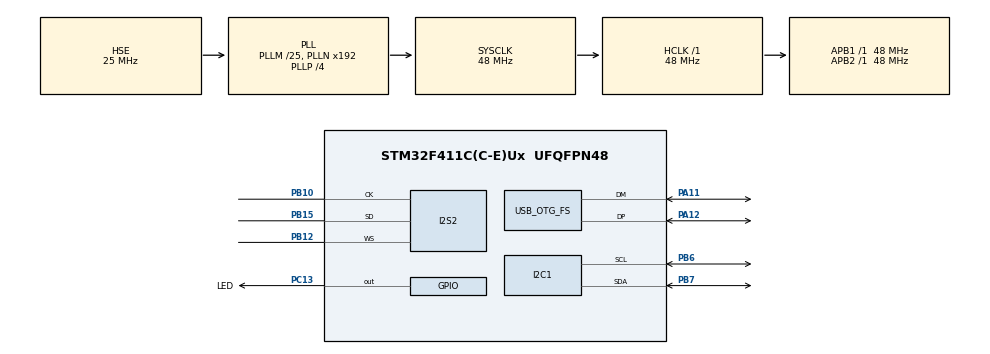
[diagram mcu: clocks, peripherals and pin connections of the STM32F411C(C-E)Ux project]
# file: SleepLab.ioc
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Dma.Request0=SPI2_RX
Dma.SPI2_RX.0.Direction=DMA_PERIPH_TO_MEMORY
Dma.SPI2_RX.0.FIFOMode=DMA_FIFOMODE_DISABLE
Dma.SPI2_RX.0.Instance=DMA1_Stream3
Dma.SPI2_RX.0.MemDataAlignment=DMA_MDATAALIGN_HALFWORD
Dma.SPI2_RX.0.MemInc=DMA_MINC_ENABLE
Dma.SPI2_RX.0.Mode=DMA_CIRCULAR
Dma.SPI2_RX.0.PeriphDataAlignment=DMA_PDATAALIGN_HALFWORD
Dma.SPI2_RX.0.PeriphInc=DMA_PINC_DISABLE
Dma.SPI2_RX.0.Priority=DMA_PRIORITY_LOW
I2S2.AudioFreq=I2S_AUDIOFREQ_32K
I2S2.DataFormat=I2S_DATAFORMAT_24B
I2S2.ErrorAudioFreq=0.33 %
I2S2.FullDuplexMode=I2S_FULLDUPLEXMODE_DISABLE
I2S2.Instance=SPI$Index
I2S2.Mode=I2S_MODE_MASTER_RX
I2S2.RealAudioFreq=32.106 KHz
I2S2.VirtualMode=I2S_MODE_MASTER
Mcu.Family=STM32F4
Mcu.Name=STM32F411C(C-E)Ux
Mcu.Package=UFQFPN48
NVIC.DMA1_Stream3_IRQn=true\:5\:0\:true\:false\:true\:false\:true\:true
NVIC.OTG_FS_IRQn=true\:0\:0\:true\:false\:true\:true\:true\:true
NVIC.PriorityGroup=NVIC_PRIORITYGROUP_4
PA11.Mode=Device_Only
PA11.Signal=USB_OTG_FS_DM
PA12.Mode=Device_Only
PA12.Signal=USB_OTG_FS_DP
PA13.Mode=Serial_Wire
PA13.Signal=SYS_JTMS-SWDIO
PA14.Mode=Serial_Wire
PA14.Signal=SYS_JTCK-SWCLK
PB10.Mode=Half_Duplex_Master
PB10.Signal=I2S2_CK
PB12.Mode=Half_Duplex_Master
PB12.Signal=I2S2_WS
PB15.Mode=Half_Duplex_Master
PB15.Signal=I2S2_SD
PB6.Mode=I2C
PB6.Signal=I2C1_SCL
PB7.Mode=I2C
PB7.Signal=I2C1_SDA
PC13-ANTI_TAMP.GPIO_Label=LED
PC13-ANTI_TAMP.GPIO_ModeDefaultOutputPP=GPIO_MODE_OUTPUT_PP
PC13-ANTI_TAMP.PinState=GPIO_PIN_SET
PC13-ANTI_TAMP.Signal=GPIO_Output
PH0\ -\ OSC_IN.Mode=HSE-External-Oscillator
PH0\ -\ OSC_IN.Signal=RCC_OSC_IN
PH1\ -\ OSC_OUT.Mode=HSE-External-Oscillator
PH1\ -\ OSC_OUT.Signal=RCC_OSC_OUT
ProjectManager.HeapSize=0x200
ProjectManager.StackSize=0x400
ProjectManager.TargetToolchain=CMake
RCC.48MHZClocksFreq_Value=48000000
RCC.AHBFreq_Value=48000000
RCC.APB1Freq_Value=48000000
RCC.APB1TimFreq_Value=48000000
RCC.APB2Freq_Value=48000000
RCC.APB2TimFreq_Value=48000000
RCC.CortexFreq_Value=48000000
RCC.HCLKFreq_Value=48000000
RCC.HSE_VALUE=25000000
RCC.HSI_VALUE=16000000
RCC.LSE_VALUE=32768
RCC.PLLM=25
RCC.PLLP=RCC_PLLP_DIV4
RCC.SYSCLKFreq_VALUE=48000000
RCC.SYSCLKSource=RCC_SYSCLKSOURCE_PLLCLK
RCC.VCOOutputFreq_Value=192000000
USB_DEVICE.CLASS_NAME_FS=CDC
USB_DEVICE.VirtualMode=Cdc
USB_DEVICE.VirtualModeFS=Cdc_FS
USB_OTG_FS.VirtualMode=Device_Only
VP_USB_DEVICE_VS_USB_DEVICE_CDC_FS.Mode=CDC_FS
board=custom

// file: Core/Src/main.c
/* USER CODE BEGIN Header */
/**
  ******************************************************************************
  * @file           : main.c
  * @brief          : Main program body
  ******************************************************************************
  * @attention
  *
  * Copyright (c) 2026 STMicroelectronics.
  * All rights reserved.
  *
  * This software is licensed under terms that can be found in the LICENSE file
  * in the root directory of this software component.
  * If no LICENSE file comes with this software, it is provided AS-IS.
  *
  ******************************************************************************
  */
/* USER CODE END Header */
#include "main.h"
#include "usb_device.h"

/* USER CODE BEGIN Includes */
#include "app.h"
#include "audio.h"
/* USER CODE END Includes */

I2C_HandleTypeDef hi2c1;

I2S_HandleTypeDef hi2s2;
DMA_HandleTypeDef hdma_spi2_rx;

void SystemClock_Config(void);
static void MX_GPIO_Init(void);
static void MX_DMA_Init(void);
static void MX_I2C1_Init(void);
static void MX_I2S2_Init(void);

int main(void)
{

  /* MCU Configuration--------------------------------------------------------*/

  /* Reset of all peripherals, Initializes the Flash interface and the Systick. */
  HAL_Init();

  /* Configure the system clock */
  SystemClock_Config();

  /* Initialize all configured peripherals */
  MX_GPIO_Init();
  MX_DMA_Init();
  MX_I2C1_Init();
  MX_USB_DEVICE_Init();
  MX_I2S2_Init();
  /* USER CODE BEGIN 2 */

  App_Init(&hi2c1);

  if (Audio_Start(&hi2s2) != HAL_OK){
      Error_Handler();
  }

  /* USER CODE END 2 */

  /* Infinite loop */
  while (1){

    /* USER CODE BEGIN 3 */
      Audio_Process();
      Audio_Update(HAL_GetTick());
      App_Update();
      __WFI();
  }
  /* USER CODE END 3 */
}

void SystemClock_Config(void)
{
  RCC_OscInitTypeDef RCC_OscInitStruct = {0};
  RCC_ClkInitTypeDef RCC_ClkInitStruct = {0};

  /** Configure the main internal regulator output voltage
  */
  __HAL_RCC_PWR_CLK_ENABLE();
  __HAL_PWR_VOLTAGESCALING_CONFIG(PWR_REGULATOR_VOLTAGE_SCALE1);

  /** Initializes the RCC Oscillators according to the specified parameters
  * in the RCC_OscInitTypeDef structure.
  */
  RCC_OscInitStruct.OscillatorType = RCC_OSCILLATORTYPE_HSE;
  RCC_OscInitStruct.HSEState = RCC_HSE_ON;
  RCC_OscInitStruct.PLL.PLLState = RCC_PLL_ON;
  RCC_OscInitStruct.PLL.PLLSource = RCC_PLLSOURCE_HSE;
  RCC_OscInitStruct.PLL.PLLM = 25;
  RCC_OscInitStruct.PLL.PLLN = 192;
  RCC_OscInitStruct.PLL.PLLP = RCC_PLLP_DIV4;
  RCC_OscInitStruct.PLL.PLLQ = 4;
  if (HAL_RCC_OscConfig(&RCC_OscInitStruct) != HAL_OK)
  {
    Error_Handler();
  }

  /** Initializes the CPU, AHB and APB buses clocks
  */
  RCC_ClkInitStruct.ClockType = RCC_CLOCKTYPE_HCLK|RCC_CLOCKTYPE_SYSCLK
                              |RCC_CLOCKTYPE_PCLK1|RCC_CLOCKTYPE_PCLK2;
  RCC_ClkInitStruct.SYSCLKSource = RCC_SYSCLKSOURCE_PLLCLK;
  RCC_ClkInitStruct.AHBCLKDivider = RCC_SYSCLK_DIV1;
  RCC_ClkInitStruct.APB1CLKDivider = RCC_HCLK_DIV1;
  RCC_ClkInitStruct.APB2CLKDivider = RCC_HCLK_DIV1;

  if (HAL_RCC_ClockConfig(&RCC_ClkInitStruct, FLASH_LATENCY_1) != HAL_OK)
  {
    Error_Handler();
  }
}

static void MX_I2C1_Init(void)
{

  hi2c1.Instance = I2C1;
  hi2c1.Init.ClockSpeed = 100000;
  hi2c1.Init.DutyCycle = I2C_DUTYCYCLE_2;
  hi2c1.Init.OwnAddress1 = 0;
  hi2c1.Init.AddressingMode = I2C_ADDRESSINGMODE_7BIT;
  hi2c1.Init.DualAddressMode = I2C_DUALADDRESS_DISABLE;
  hi2c1.Init.OwnAddress2 = 0;
  hi2c1.Init.GeneralCallMode = I2C_GENERALCALL_DISABLE;
  hi2c1.Init.NoStretchMode = I2C_NOSTRETCH_DISABLE;
  if (HAL_I2C_Init(&hi2c1) != HAL_OK)
  {
    Error_Handler();
  }

}

static void MX_I2S2_Init(void)
{

  hi2s2.Instance = SPI2;
  hi2s2.Init.Mode = I2S_MODE_MASTER_RX;
  hi2s2.Init.Standard = I2S_STANDARD_PHILIPS;
  hi2s2.Init.DataFormat = I2S_DATAFORMAT_24B;
  hi2s2.Init.MCLKOutput = I2S_MCLKOUTPUT_DISABLE;
  hi2s2.Init.AudioFreq = I2S_AUDIOFREQ_32K;
  hi2s2.Init.CPOL = I2S_CPOL_LOW;
  hi2s2.Init.ClockSource = I2S_CLOCK_PLL;
  hi2s2.Init.FullDuplexMode = I2S_FULLDUPLEXMODE_DISABLE;
  if (HAL_I2S_Init(&hi2s2) != HAL_OK)
  {
    Error_Handler();
  }

}

static void MX_DMA_Init(void)
{

  /* DMA controller clock enable */
  __HAL_RCC_DMA1_CLK_ENABLE();

  /* DMA interrupt init */
  /* DMA1_Stream3_IRQn interrupt configuration */
  HAL_NVIC_SetPriority(DMA1_Stream3_IRQn, 5, 0);
  HAL_NVIC_EnableIRQ(DMA1_Stream3_IRQn);

}

static void MX_GPIO_Init(void)
{
  GPIO_InitTypeDef GPIO_InitStruct = {0};

  /* GPIO Ports Clock Enable */
  __HAL_RCC_GPIOC_CLK_ENABLE();
  __HAL_RCC_GPIOH_CLK_ENABLE();
  __HAL_RCC_GPIOB_CLK_ENABLE();
  __HAL_RCC_GPIOA_CLK_ENABLE();

  /*Configure GPIO pin Output Level */
  HAL_GPIO_WritePin(LED_GPIO_Port, LED_Pin, GPIO_PIN_SET);

  /*Configure GPIO pin : LED_Pin */
  GPIO_InitStruct.Pin = LED_Pin;
  GPIO_InitStruct.Mode = GPIO_MODE_OUTPUT_PP;
  GPIO_InitStruct.Pull = GPIO_NOPULL;
  GPIO_InitStruct.Speed = GPIO_SPEED_FREQ_LOW;
  HAL_GPIO_Init(LED_GPIO_Port, &GPIO_InitStruct);

}

void Error_Handler(void)
{
  __disable_irq();
  while (1)
  {
  }
}
